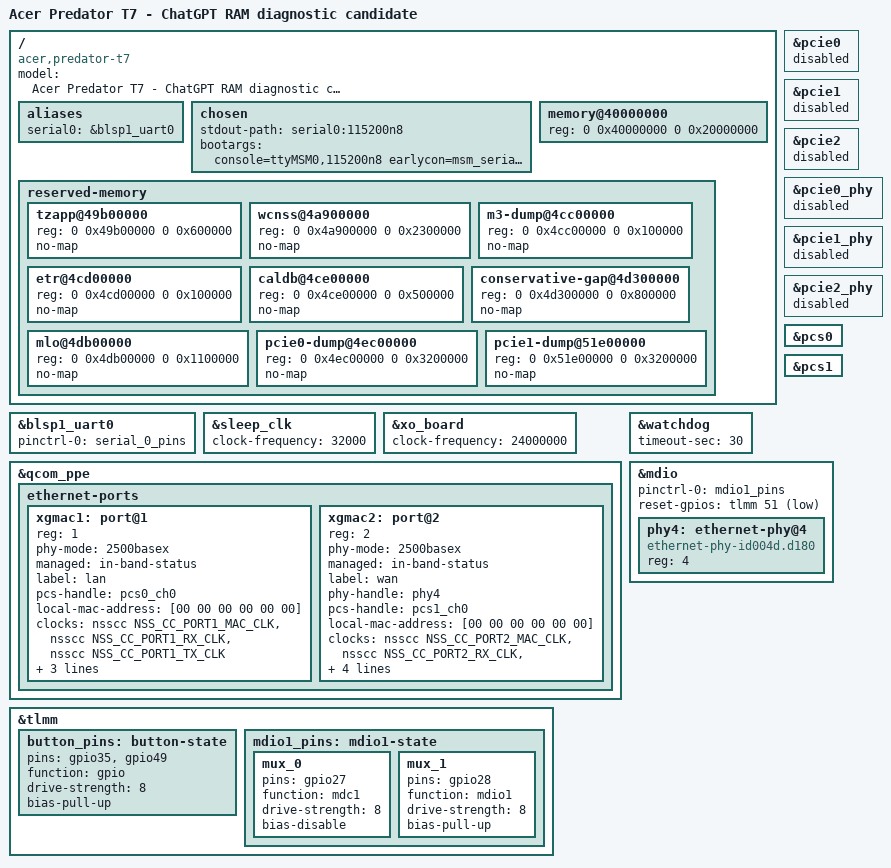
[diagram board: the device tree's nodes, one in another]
// Diagnostico candidato; NAO aprovado para upload.
/dts-v1/;
#include "qcom/ipq5332.dtsi"
#include <dt-bindings/gpio/gpio.h>
/ {
    model = "Acer Predator T7 - ChatGPT RAM diagnostic candidate";
    compatible = "acer,predator-t7", "qcom,ipq5332-ap-mi01.6", "qcom,ipq5332";
    aliases { serial0 = &blsp1_uart0; };
    chosen {
        stdout-path = "serial0:115200n8";
        bootargs = "console=ttyMSM0,115200n8 earlycon=msm_serial_dm,0x78af000 loglevel=8 ignore_loglevel panic=0 maxcpus=1 rdinit=/init netconsole=6665@169.254.73.2/lan,6667@169.254.73.1/ff:ff:ff:ff:ff:ff";
    };
    /* Conservative 512 MiB template; actual banks/fixups must be confirmed. */
    memory@40000000 { reg = <0 0x40000000 0 0x20000000>; };
    reserved-memory {
        tzapp@49b00000 { reg = <0 0x49b00000 0 0x600000>; no-map; };
        wcnss@4a900000 { reg = <0 0x4a900000 0 0x2300000>; no-map; };
        m3-dump@4cc00000 { reg = <0 0x4cc00000 0 0x100000>; no-map; };
        etr@4cd00000 { reg = <0 0x4cd00000 0 0x100000>; no-map; };
        caldb@4ce00000 { reg = <0 0x4ce00000 0 0x500000>; no-map; };
        conservative-gap@4d300000 { reg = <0 0x4d300000 0 0x800000>; no-map; };
        mlo@4db00000 { reg = <0 0x4db00000 0 0x1100000>; no-map; };
        pcie0-dump@4ec00000 { reg = <0 0x4ec00000 0 0x3200000>; no-map; };
        pcie1-dump@51e00000 { reg = <0 0x51e00000 0 0x3200000>; no-map; };
        /* No ramoops reg: exclusive location and reset retention unverified. */
    };
};
&blsp1_uart0 {
    pinctrl-0 = <&serial_0_pins>;
    pinctrl-names = "default";
    status = "okay";
};
&sleep_clk { clock-frequency = <32000>; };
&xo_board { clock-frequency = <24000000>; };
&qcom_ppe {
	status = "okay";

	ethernet-ports {
		#address-cells = <1>;
		#size-cells = <0>;

		xgmac1: port@1 {
			reg = <1>;
			phy-mode = "2500basex";
			managed = "in-band-status";
			label = "lan";
			pcs-handle = <&pcs0_ch0>;
			local-mac-address = [00 00 00 00 00 00];
			clocks = <&nsscc NSS_CC_PORT1_MAC_CLK>,
				 <&nsscc NSS_CC_PORT1_RX_CLK>,
				 <&nsscc NSS_CC_PORT1_TX_CLK>;
			clock-names = "mac",
				      "rx",
				      "tx";
			resets = <&nsscc NSS_CC_PORT1_MAC_CLK_ARES>,
				 <&nsscc NSS_CC_PORT1_RX_CLK_ARES>,
				 <&nsscc NSS_CC_PORT1_TX_CLK_ARES>;
			reset-names = "mac",
				      "rx",
				      "tx";
		};

		xgmac2: port@2 {
			reg = <2>;
			phy-mode = "2500basex";
			managed = "in-band-status";
			label = "wan";
			phy-handle = <&phy4>;
			pcs-handle = <&pcs1_ch0>;
			local-mac-address = [00 00 00 00 00 00];
			clocks = <&nsscc NSS_CC_PORT2_MAC_CLK>,
				 <&nsscc NSS_CC_PORT2_RX_CLK>,
				 <&nsscc NSS_CC_PORT2_TX_CLK>;
			clock-names = "mac",
				      "rx",
				      "tx";
			resets = <&nsscc NSS_CC_PORT2_MAC_CLK_ARES>,
				 <&nsscc NSS_CC_PORT2_RX_CLK_ARES>,
				 <&nsscc NSS_CC_PORT2_TX_CLK_ARES>;
			reset-names = "mac",
				      "rx",
				      "tx";
		};
	};
};
&pcie0 { status = "disabled"; };
&pcie1 { status = "disabled"; };
&pcie2 { status = "disabled"; };
&pcie0_phy { status = "disabled"; };
&pcie1_phy { status = "disabled"; };
&pcie2_phy { status = "disabled"; };
&watchdog { status = "okay"; timeout-sec = <30>; };

&pcs0 {
	status = "okay";
};
&pcs1 {
	status = "okay";
};
&mdio {
	status = "okay";

	pinctrl-names = "default";
	pinctrl-0 = <&mdio1_pins>;
	reset-gpios = <&tlmm 51 GPIO_ACTIVE_LOW>;

	phy4: ethernet-phy@4 {
		compatible = "ethernet-phy-id004d.d180";
		reg = <4>;
	};
};
&tlmm {
	button_pins: button-state {
		pins = "gpio35", "gpio49";
		function = "gpio";
		drive-strength = <8>;
		bias-pull-up;
	};

	mdio1_pins: mdio1-state {
		mux_0 {
			pins = "gpio27";
			function = "mdc1";
			drive-strength = <8>;
			bias-disable;
		};

		mux_1 {
			pins = "gpio28";
			function = "mdio1";
			drive-strength = <8>;
			bias-pull-up;
		};
	};
};
